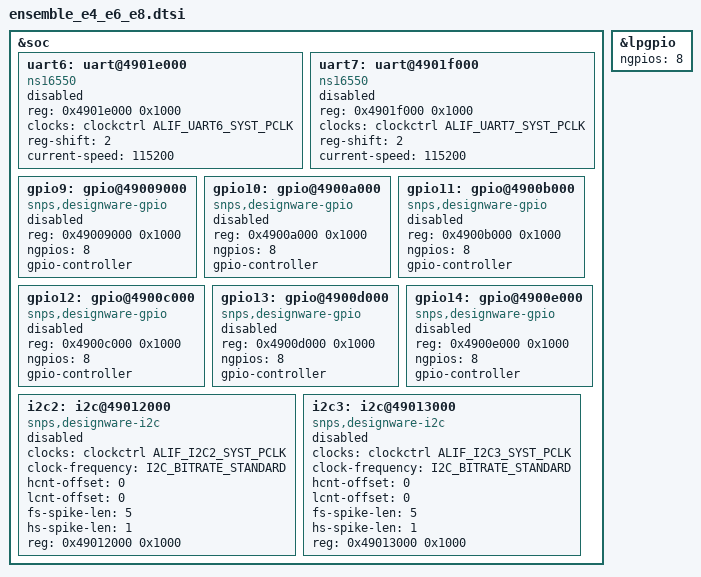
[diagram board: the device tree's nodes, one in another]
/*
 * SPDX-FileCopyrightText: Copyright Alif Semiconductor
 * SPDX-License-Identifier: Apache-2.0
 */

/*
 * Peripherals shared by the E4, E6 and E8 Ensemble SoCs that are additional
 * to the minimum common subset (see ensemble_common.dtsi). As with the common
 * layer, interrupt routing is intentionally kept out of this file and lives in
 * the controller-specific ensemble_e4_e6_e8_{nvic,gic}_irq.dtsi files.
 */

#include <alif/ensemble/common/ensemble_common.dtsi>

&soc {
	uart6: uart@4901e000 {
		compatible = "ns16550";
		reg = <0x4901e000 0x1000>;
		clocks = <&clockctrl ALIF_UART6_SYST_PCLK>;
		reg-shift = <2>;
		current-speed = <115200>;
		status = "disabled";
	};

	uart7: uart@4901f000 {
		compatible = "ns16550";
		reg = <0x4901f000 0x1000>;
		clocks = <&clockctrl ALIF_UART7_SYST_PCLK>;
		reg-shift = <2>;
		current-speed = <115200>;
		status = "disabled";
	};

	gpio9: gpio@49009000 {
		compatible = "snps,designware-gpio";
		reg = <0x49009000 0x1000>;
		ngpios = <8>;
		gpio-controller;
		#gpio-cells = <2>;
		status = "disabled";
	};

	gpio10: gpio@4900a000 {
		compatible = "snps,designware-gpio";
		reg = <0x4900a000 0x1000>;
		ngpios = <8>;
		gpio-controller;
		#gpio-cells = <2>;
		status = "disabled";
	};

	gpio11: gpio@4900b000 {
		compatible = "snps,designware-gpio";
		reg = <0x4900b000 0x1000>;
		ngpios = <8>;
		gpio-controller;
		#gpio-cells = <2>;
		status = "disabled";
	};

	gpio12: gpio@4900c000 {
		compatible = "snps,designware-gpio";
		reg = <0x4900c000 0x1000>;
		ngpios = <8>;
		gpio-controller;
		#gpio-cells = <2>;
		status = "disabled";
	};

	gpio13: gpio@4900d000 {
		compatible = "snps,designware-gpio";
		reg = <0x4900d000 0x1000>;
		ngpios = <8>;
		gpio-controller;
		#gpio-cells = <2>;
		status = "disabled";
	};

	gpio14: gpio@4900e000 {
		compatible = "snps,designware-gpio";
		reg = <0x4900e000 0x1000>;
		ngpios = <8>;
		gpio-controller;
		#gpio-cells = <2>;
		status = "disabled";
	};

	/*
	 * DesignWare I2C controllers.
	 * hcnt-offset / lcnt-offset are the tuning offsets applied on top
	 * of the values computed from the input clock and target speed.
	 * Verify against the target board layout and adjust per instance if needed.
	 */
	i2c2: i2c@49012000 {
		compatible = "snps,designware-i2c";
		clocks = <&clockctrl ALIF_I2C2_SYST_PCLK>;
		clock-frequency = <I2C_BITRATE_STANDARD>;
		hcnt-offset = <0>;
		lcnt-offset = <0>;
		fs-spike-len = <5>;
		hs-spike-len = <1>;
		#address-cells = <1>;
		#size-cells = <0>;
		reg = <0x49012000 0x1000>;
		status = "disabled";
	};

	i2c3: i2c@49013000 {
		compatible = "snps,designware-i2c";
		clocks = <&clockctrl ALIF_I2C3_SYST_PCLK>;
		clock-frequency = <I2C_BITRATE_STANDARD>;
		hcnt-offset = <0>;
		lcnt-offset = <0>;
		fs-spike-len = <5>;
		hs-spike-len = <1>;
		#address-cells = <1>;
		#size-cells = <0>;
		reg = <0x49013000 0x1000>;
		status = "disabled";
	};
};

/* These devices carry the full eight pin wide LPGPIO. */
&lpgpio {
	ngpios = <8>;
};
